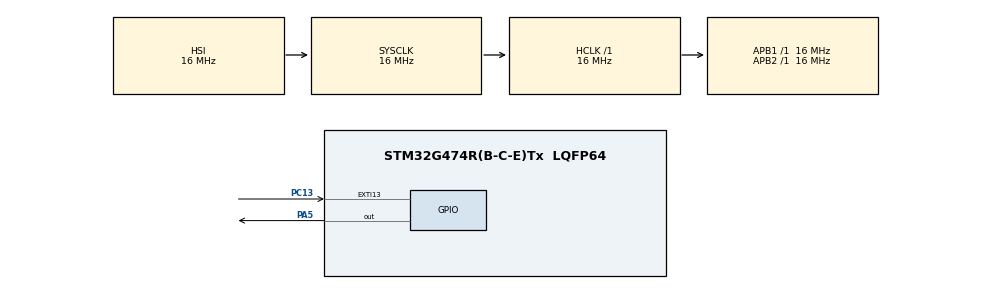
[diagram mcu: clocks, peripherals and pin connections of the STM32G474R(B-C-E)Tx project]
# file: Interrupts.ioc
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Mcu.Family=STM32G4
Mcu.Name=STM32G474R(B-C-E)Tx
Mcu.Package=LQFP64
NVIC.EXTI15_10_IRQn=true\:2\:0\:true\:false\:true\:true\:true\:true
NVIC.PriorityGroup=NVIC_PRIORITYGROUP_4
PA5.Signal=GPIO_Output
PC13.GPIO_ModeDefaultEXTI=GPIO_MODE_IT_FALLING
PC13.GPIO_PuPd=GPIO_NOPULL
PC13.Signal=GPXTI13
ProjectManager.HeapSize=0x200
ProjectManager.StackSize=0x400
ProjectManager.TargetToolchain=STM32CubeIDE
RCC.AHBFreq_Value=16000000
RCC.APB1Freq_Value=16000000
RCC.APB1TimFreq_Value=16000000
RCC.APB2Freq_Value=16000000
RCC.APB2TimFreq_Value=16000000
RCC.CortexFreq_Value=16000000
RCC.EXTERNAL_CLOCK_VALUE=12288000
RCC.HCLKFreq_Value=16000000
RCC.HSE_VALUE=8000000
RCC.HSI48_VALUE=48000000
RCC.HSI_VALUE=16000000
RCC.LSE_VALUE=32768
RCC.SYSCLKFreq_VALUE=16000000
RCC.USBFreq_Value=64000000
RCC.VCOOutputFreq_Value=128000000
board=custom

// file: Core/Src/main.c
/* USER CODE BEGIN Header */
/**
  ******************************************************************************
  * @file           : main.c
  * @brief          : Main program body
  ******************************************************************************
  * @attention
  *
  * Copyright (c) 2025 STMicroelectronics.
  * All rights reserved.
  *
  ******************************************************************************
  */
/* USER CODE END Header */
#include "main.h"

/* USER CODE BEGIN PTD */
typedef struct {
    uint32_t led_blink_period_ms;      /* LED yanıp sönme periyodu (ms) */
    uint32_t led_blink_timestamp_ms;   /* Son LED toggle zamanı (ms) */
} LedTaskVars;
/* USER CODE END PTD */

/* USER CODE BEGIN PV */
static LedTaskVars led_task = {
    .led_blink_period_ms    = 250,
    .led_blink_timestamp_ms = 0
};
/* USER CODE END PV */

void SystemClock_Config(void);
static void MX_GPIO_Init(void);
/* USER CODE BEGIN PFP */
/**
  * @brief  LED toggle işlevi: mevcut periyoda göre toggle eder
  */
static void led_blink_task(void)
{
    uint32_t current_time = HAL_GetTick();
    if ((current_time - led_task.led_blink_timestamp_ms) >= led_task.led_blink_period_ms)
    {
        led_task.led_blink_timestamp_ms = current_time;
        HAL_GPIO_TogglePin(GPIOA, GPIO_PIN_5);
    }
}
/* USER CODE END PFP */

/* USER CODE BEGIN 0 */
/**
  * @brief  EXTI kesme callback: PC13 pinindeki interrupt buraya düşer
  */
void HAL_GPIO_EXTI_Callback(uint16_t GPIO_Pin)
{
    static uint32_t last_irq_time_ms = 0;
    uint32_t current_time = HAL_GetTick();

    if (GPIO_Pin == GPIO_PIN_13)
    {
        /* Debounce: 40 ms içinde tekrar gelirse yok say */
        if ((current_time - last_irq_time_ms) < 40) return;
        last_irq_time_ms = current_time;

        /* Her basışta periyodu +250 ms artır, 2000 ms’yi geçince 250 ms’e resetle */
        led_task.led_blink_period_ms += 250;
        if (led_task.led_blink_period_ms > 2000)
        {
            led_task.led_blink_period_ms = 250;
        }
    }
}
/* USER CODE END 0 */

int main(void)
{

  /* MCU Configuration--------------------------------------------------------*/

  /* Reset of all peripherals, Initializes the Flash interface and the Systick. */
  HAL_Init();

  /* Configure the system clock */
  SystemClock_Config();

  /* Initialize all configured peripherals */
  MX_GPIO_Init();

  /* Infinite loop */
  /* USER CODE BEGIN WHILE */
  while (1)
  {
	        led_blink_task();
    /* USER CODE END WHILE */

  }
}

void SystemClock_Config(void)
{
  RCC_OscInitTypeDef RCC_OscInitStruct = {0};
  RCC_ClkInitTypeDef RCC_ClkInitStruct = {0};

  /** Configure the main internal regulator output voltage
  */
  HAL_PWREx_ControlVoltageScaling(PWR_REGULATOR_VOLTAGE_SCALE1);

  /** Initializes the RCC Oscillators according to the specified parameters
  * in the RCC_OscInitTypeDef structure.
  */
  RCC_OscInitStruct.OscillatorType = RCC_OSCILLATORTYPE_HSI;
  RCC_OscInitStruct.HSIState = RCC_HSI_ON;
  RCC_OscInitStruct.HSICalibrationValue = RCC_HSICALIBRATION_DEFAULT;
  RCC_OscInitStruct.PLL.PLLState = RCC_PLL_NONE;
  if (HAL_RCC_OscConfig(&RCC_OscInitStruct) != HAL_OK)
  {
    Error_Handler();
  }

  /** Initializes the CPU, AHB and APB buses clocks
  */
  RCC_ClkInitStruct.ClockType = RCC_CLOCKTYPE_HCLK|RCC_CLOCKTYPE_SYSCLK
                              |RCC_CLOCKTYPE_PCLK1|RCC_CLOCKTYPE_PCLK2;
  RCC_ClkInitStruct.SYSCLKSource = RCC_SYSCLKSOURCE_HSI;
  RCC_ClkInitStruct.AHBCLKDivider = RCC_SYSCLK_DIV1;
  RCC_ClkInitStruct.APB1CLKDivider = RCC_HCLK_DIV1;
  RCC_ClkInitStruct.APB2CLKDivider = RCC_HCLK_DIV1;

  if (HAL_RCC_ClockConfig(&RCC_ClkInitStruct, FLASH_LATENCY_0) != HAL_OK)
  {
    Error_Handler();
  }
}

static void MX_GPIO_Init(void)
{
  GPIO_InitTypeDef GPIO_InitStruct = {0};

  /* GPIO Ports Clock Enable */
  __HAL_RCC_GPIOC_CLK_ENABLE();
  __HAL_RCC_GPIOA_CLK_ENABLE();

  /*Configure GPIO pin Output Level */
  HAL_GPIO_WritePin(GPIOA, GPIO_PIN_5, GPIO_PIN_RESET);

  /*Configure GPIO pin : PC13 */
  GPIO_InitStruct.Pin = GPIO_PIN_13;
  GPIO_InitStruct.Mode = GPIO_MODE_IT_FALLING;
  GPIO_InitStruct.Pull = GPIO_NOPULL;
  HAL_GPIO_Init(GPIOC, &GPIO_InitStruct);

  /*Configure GPIO pin : PA5 */
  GPIO_InitStruct.Pin = GPIO_PIN_5;
  GPIO_InitStruct.Mode = GPIO_MODE_OUTPUT_PP;
  GPIO_InitStruct.Pull = GPIO_NOPULL;
  GPIO_InitStruct.Speed = GPIO_SPEED_FREQ_LOW;
  HAL_GPIO_Init(GPIOA, &GPIO_InitStruct);

  /* EXTI interrupt init*/
  HAL_NVIC_SetPriority(EXTI15_10_IRQn, 2, 0);
  HAL_NVIC_EnableIRQ(EXTI15_10_IRQn);

}

void Error_Handler(void)
{
    __disable_irq();
    while (1)
    {
    }
}
